AUTOSAR XML (schema 4-2-2)
package /Components
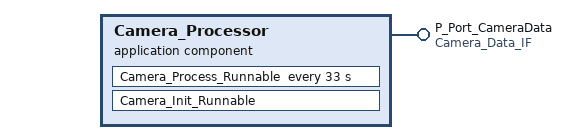
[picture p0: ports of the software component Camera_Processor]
  application sw component type Camera_Processor
    provide port P_Port_CameraData: provided-interface=Camera_Data_IF
    behavior Camera_Processor_InternalBehavior
      init event Camera_Init_Event: start-on-event=Camera_Init_Runnable
      timing event Camera_Process_Event: start-on-event=Camera_Process_Runnable, period=33
      runnable Camera_Init_Runnable: symbol=Camera_Init
        parameter access PA_Init_Camera_Params_LaneModel: accessed-parameter=P_Port_CameraData.Camera_LaneModel
        parameter access PA_Init_Camera_Params_ObjectList: accessed-parameter=P_Port_CameraData.Camera_ObjectList
      runnable Camera_Process_Runnable: minimum-start-interval=33, symbol=Camera_Process
        data-send-points:
          access VA_Send_Camera_LaneModel: accessed-variable=P_Port_CameraData.Camera_LaneModel
          access VA_Send_Camera_ObjectList: accessed-variable=P_Port_CameraData.Camera_ObjectList
        parameter access PA_Run_Camera_Params_LaneModel: accessed-parameter=P_Port_CameraData.Camera_LaneModel
        parameter access PA_Run_Camera_Params_ObjectList: accessed-parameter=P_Port_CameraData.Camera_ObjectList
